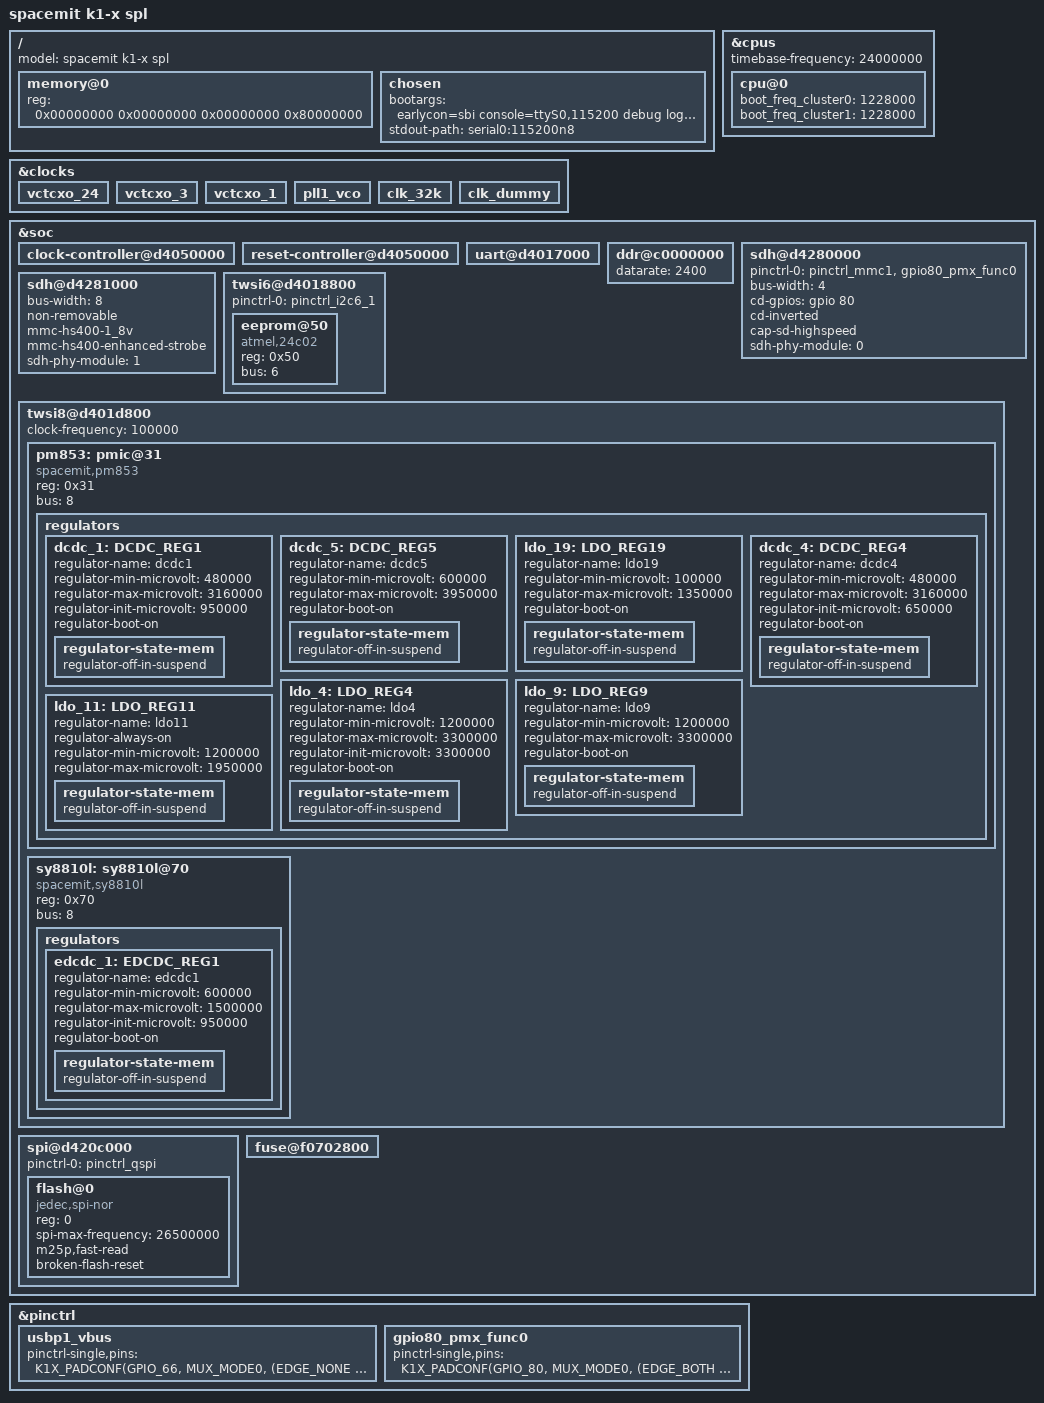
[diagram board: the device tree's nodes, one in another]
// SPDX-License-Identifier: (GPL-2.0 OR MIT)
/* Copyright (c) 2023 Spacemit, Inc */

/dts-v1/;

#include "k1-x.dtsi"
#include "k1-x_pinctrl.dtsi"

/ {
	model = "spacemit k1-x spl";

	memory@0 {
		device_type = "memory";
		reg = <0x00000000 0x00000000 0x00000000 0x80000000>;
		u-boot,dm-spl;
	};

	chosen {
		bootargs = "earlycon=sbi console=ttyS0,115200 debug loglevel=8,initcall_debug=1 rdinit=/init.tmp";
		stdout-path = "serial0:115200n8";
		u-boot,dm-spl;
	};
};

&cpus {
	timebase-frequency = <24000000>;
	u-boot,dm-spl;

	cpu@0 {
		/* boot frequency for cluster-0, should be 1600000, 1228000, 819000, or 614000 */
		boot_freq_cluster0 = <1228000>;
		/* boot frequency for cluster-1, should be 1600000, 1228000, 819000, or 614000 */
		boot_freq_cluster1 = <1228000>;
		u-boot,dm-spl;
	};
};

&clocks {
	u-boot,dm-spl;

	vctcxo_24 {
		u-boot,dm-spl;
	};

	vctcxo_3 {
		u-boot,dm-spl;
	};

	vctcxo_1 {
		u-boot,dm-spl;
	};

	pll1_vco {
		u-boot,dm-spl;
	};

	clk_32k {
		u-boot,dm-spl;
	};

	clk_dummy {
		u-boot,dm-spl;
	};
};

&soc {
	u-boot,dm-spl;

	clock-controller@d4050000 {
		status = "okay";
		u-boot,dm-spl;
	};

	reset-controller@d4050000 {
		status = "okay";
		u-boot,dm-spl;
	};

	uart@d4017000 {
		status = "okay";
		u-boot,dm-spl;
	};

	ddr@c0000000 {
		/* dram data rate, should be 1200, 1600, or 2400 */
		datarate = <2400>;
		u-boot,dm-spl;
	};

	sdh@d4280000 {
		pinctrl-names = "default";
		pinctrl-0 = <&pinctrl_mmc1 &gpio80_pmx_func0>;
		bus-width = <4>;
		cd-gpios = <&gpio 80 0>;
		cd-inverted;
		cap-sd-highspeed;
		sdh-phy-module = <0>;
		status = "okay";
		u-boot,dm-spl;
	};

	/* eMMC */
	sdh@d4281000 {
		bus-width = <8>;
		non-removable;
		mmc-hs400-1_8v;
		mmc-hs400-enhanced-strobe;
		sdh-phy-module = <1>;
		status = "okay";
		u-boot,dm-spl;
	};

	twsi6@d4018800 {
		#address-cells = <1>;
		#size-cells = <0>;
		pinctrl-names = "default";
		pinctrl-0 = <&pinctrl_i2c6_1>;
		status = "okay";

		eeprom@50{
			compatible = "atmel,24c02";
			reg = <0x50>;
			bus = <6>;
			#address-cells = <1>;
			#size-cells = <1>;
			status = "okay";
		};
	};

	twsi8@d401d800 {
		/* PWR_I2C */
		clock-frequency = <100000>;
		u-boot,dm-spl;
		status = "okay";

		pm853: pmic@31 {
			compatible = "spacemit,pm853";
			reg = <0x31>;
			bus = <8>;
			u-boot,dm-spl;

			regulators {
				/* buck */
				dcdc_1: DCDC_REG1 {
					regulator-name = "dcdc1";
					regulator-min-microvolt = <480000>;
					regulator-max-microvolt = <3160000>;
					regulator-init-microvolt = <950000>;
					regulator-boot-on;
					u-boot,dm-spl;
					regulator-state-mem {
						regulator-off-in-suspend;
						u-boot,dm-spl;
					};
				};

				/**
				* the order of powering on
				* 1. dcdc5
				* 2. ldo19
				* 3. dcdc4
				* 4. ldo4
				* 5. ldo9
				*/
				dcdc_5: DCDC_REG5 {
					regulator-name = "dcdc5";
					regulator-min-microvolt = <600000>;
					regulator-max-microvolt = <3950000>;
					regulator-boot-on;
					u-boot,dm-spl;
					regulator-state-mem {
						regulator-off-in-suspend;
						u-boot,dm-spl;
					};
				};

				ldo_19: LDO_REG19 {
					regulator-name = "ldo19";
					regulator-min-microvolt = <100000>;
					regulator-max-microvolt = <1350000>;
					regulator-boot-on;
					u-boot,dm-spl;
					regulator-state-mem {
						regulator-off-in-suspend;
						u-boot,dm-spl;
					};
				};

				dcdc_4: DCDC_REG4 {
					regulator-name = "dcdc4";
					regulator-min-microvolt = <480000>;
					regulator-max-microvolt = <3160000>;
					regulator-init-microvolt = <650000>;
					regulator-boot-on;
					u-boot,dm-spl;
					regulator-state-mem {
						regulator-off-in-suspend;
						u-boot,dm-spl;
					};
				};

				ldo_4: LDO_REG4 {
					regulator-name = "ldo4";
					regulator-min-microvolt = <1200000>;
					regulator-max-microvolt = <3300000>;
					regulator-init-microvolt = <3300000>;
					regulator-boot-on;
					u-boot,dm-spl;
					regulator-state-mem {
						regulator-off-in-suspend;
						u-boot,dm-spl;
					};
				};

				ldo_9: LDO_REG9 {
					regulator-name = "ldo9";
					regulator-min-microvolt = <1200000>;
					regulator-max-microvolt = <3300000>;
					regulator-boot-on;
					u-boot,dm-spl;
					regulator-state-mem {
						regulator-off-in-suspend;
						u-boot,dm-spl;
					};
				};

				ldo_11: LDO_REG11 {
					regulator-name = "ldo11";
					regulator-always-on;
					regulator-min-microvolt = <1200000>;
					regulator-max-microvolt = <1950000>;
					regulator-state-mem {
					regulator-off-in-suspend;
					u-boot,dm-spl;
					};
				};
			};
		};

		sy8810l: sy8810l@70 {
			compatible = "spacemit,sy8810l";
			reg = <0x70>;
			bus = <8>;
			u-boot,dm-spl;

			regulators {
				u-boot,dm-spl;

				edcdc_1: EDCDC_REG1 {
					regulator-name = "edcdc1";
					regulator-min-microvolt = <600000>;
					regulator-max-microvolt = <1500000>;
					regulator-init-microvolt = <950000>;
					regulator-boot-on;
					u-boot,dm-spl;
					regulator-state-mem {
						regulator-off-in-suspend;
						u-boot,dm-spl;
					};
				};
			};
		};
	};

	spi@d420c000 {
		status = "okay";
		pinctrl-names = "default";
		pinctrl-0 = <&pinctrl_qspi>;
		u-boot,dm-spl;

		flash@0 {
			compatible = "jedec,spi-nor";
			reg = <0>;
			spi-max-frequency = <26500000>;

			m25p,fast-read;
			broken-flash-reset;
			u-boot,dm-spl;
			status = "okay";
		};
	};

	fuse@f0702800 {
		status = "okay";
		u-boot,dm-spl;
	};
};

&pinctrl {
	usbp1_vbus: usbp1_vbus {
		pinctrl-single,pins =<
			K1X_PADCONF(GPIO_66, MUX_MODE0, (EDGE_NONE | PULL_UP | PAD_1V8_DS2))	/* drive_vbus1_iso */
		>;
	};

	gpio80_pmx_func0: gpio80_pmx_func0 {
		pinctrl-single,pins = <
			K1X_PADCONF(GPIO_80, MUX_MODE0, (EDGE_BOTH | PULL_UP | PAD_3V_DS4))  /* mmc cd */
		>;
	};
};

